AUTOSAR XML (schema 4-0-3)
standard types defined: UInt32
package /PATAC/MSM/ComponentTypes
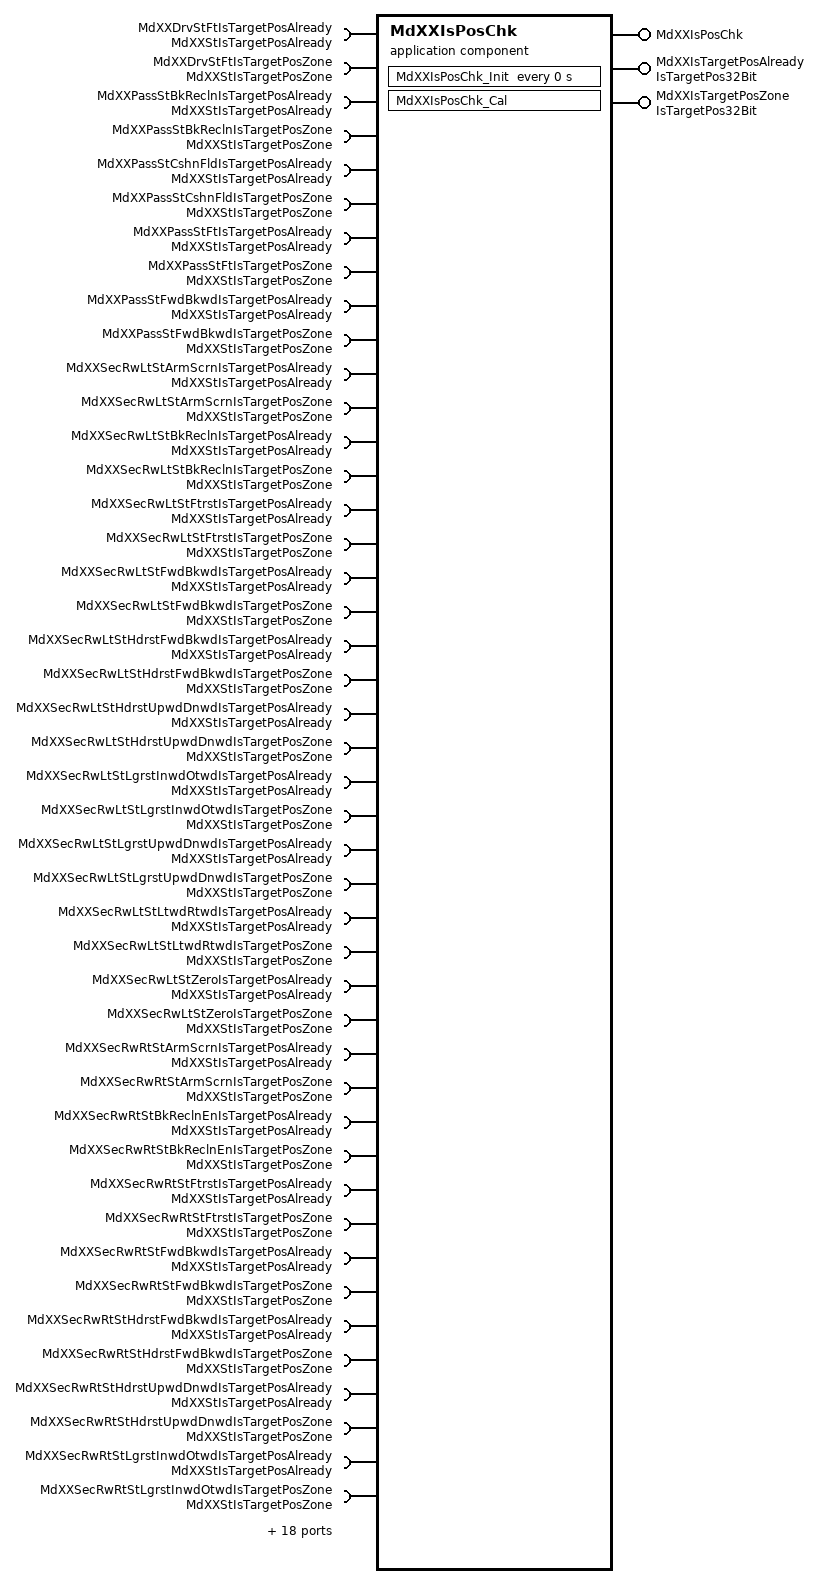
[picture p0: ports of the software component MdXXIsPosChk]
  application sw component type MdXXIsPosChk
    provide port MdXXIsPosChk: server-com-spec{operation=Cal, queue-length=1}, provided-interface=MdXXIsPosChk
    provide port MdXXIsTargetPosAlready: nonqueued-sender-com-spec{data-element=IsTargetPos32Bit/Val, init-value=0}, provided-interface=IsTargetPos32Bit
    provide port MdXXIsTargetPosZone: nonqueued-sender-com-spec{data-element=IsTargetPos32Bit/Val, init-value=0}, provided-interface=IsTargetPos32Bit
    62 x require port:
      MdXXDrvStFtIsTargetPosAlready: nonqueued-receiver-com-spec{data-element=MdXXStIsTargetPosAlready/Val, filter=data-filter-type=ALWAYS, init-value=0}, required-interface=MdXXStIsTargetPosAlready
      MdXXDrvStFtIsTargetPosZone: nonqueued-receiver-com-spec{data-element=MdXXStIsTargetPosZone/Val, filter=data-filter-type=ALWAYS, init-value=0}, required-interface=MdXXStIsTargetPosZone
      MdXXPassStBkReclnIsTargetPosAlready: nonqueued-receiver-com-spec{data-element=MdXXStIsTargetPosAlready/Val, filter=data-filter-type=ALWAYS, init-value=0}, required-interface=MdXXStIsTargetPosAlready
      MdXXPassStBkReclnIsTargetPosZone: nonqueued-receiver-com-spec{data-element=MdXXStIsTargetPosZone/Val, filter=data-filter-type=ALWAYS, init-value=0}, required-interface=MdXXStIsTargetPosZone
      MdXXPassStCshnFldIsTargetPosAlready: nonqueued-receiver-com-spec{data-element=MdXXStIsTargetPosAlready/Val, filter=data-filter-type=ALWAYS, init-value=0}, required-interface=MdXXStIsTargetPosAlready
      MdXXPassStCshnFldIsTargetPosZone: nonqueued-receiver-com-spec{data-element=MdXXStIsTargetPosZone/Val, filter=data-filter-type=ALWAYS, init-value=0}, required-interface=MdXXStIsTargetPosZone
      MdXXPassStFtIsTargetPosAlready: nonqueued-receiver-com-spec{data-element=MdXXStIsTargetPosAlready/Val, filter=data-filter-type=ALWAYS, init-value=0}, required-interface=MdXXStIsTargetPosAlready
      MdXXPassStFtIsTargetPosZone: nonqueued-receiver-com-spec{data-element=MdXXStIsTargetPosZone/Val, filter=data-filter-type=ALWAYS, init-value=0}, required-interface=MdXXStIsTargetPosZone
      MdXXPassStFwdBkwdIsTargetPosAlready: nonqueued-receiver-com-spec{data-element=MdXXStIsTargetPosAlready/Val, filter=data-filter-type=ALWAYS, init-value=0}, required-interface=MdXXStIsTargetPosAlready
      MdXXPassStFwdBkwdIsTargetPosZone: nonqueued-receiver-com-spec{data-element=MdXXStIsTargetPosZone/Val, filter=data-filter-type=ALWAYS, init-value=0}, required-interface=MdXXStIsTargetPosZone
      MdXXSecRwLtStArmScrnIsTargetPosAlready: nonqueued-receiver-com-spec{data-element=MdXXStIsTargetPosAlready/Val, filter=data-filter-type=ALWAYS, init-value=0}, required-interface=MdXXStIsTargetPosAlready
      MdXXSecRwLtStArmScrnIsTargetPosZone: nonqueued-receiver-com-spec{data-element=MdXXStIsTargetPosZone/Val, filter=data-filter-type=ALWAYS, init-value=0}, required-interface=MdXXStIsTargetPosZone
      MdXXSecRwLtStBkReclnIsTargetPosAlready: nonqueued-receiver-com-spec{data-element=MdXXStIsTargetPosAlready/Val, filter=data-filter-type=ALWAYS, init-value=0}, required-interface=MdXXStIsTargetPosAlready
      MdXXSecRwLtStBkReclnIsTargetPosZone: nonqueued-receiver-com-spec{data-element=MdXXStIsTargetPosZone/Val, filter=data-filter-type=ALWAYS, init-value=0}, required-interface=MdXXStIsTargetPosZone
      MdXXSecRwLtStFtrstIsTargetPosAlready: nonqueued-receiver-com-spec{data-element=MdXXStIsTargetPosAlready/Val, filter=data-filter-type=ALWAYS, init-value=0}, required-interface=MdXXStIsTargetPosAlready
      MdXXSecRwLtStFtrstIsTargetPosZone: nonqueued-receiver-com-spec{data-element=MdXXStIsTargetPosZone/Val, filter=data-filter-type=ALWAYS, init-value=0}, required-interface=MdXXStIsTargetPosZone
      MdXXSecRwLtStFwdBkwdIsTargetPosAlready: nonqueued-receiver-com-spec{data-element=MdXXStIsTargetPosAlready/Val, filter=data-filter-type=ALWAYS, init-value=0}, required-interface=MdXXStIsTargetPosAlready
      MdXXSecRwLtStFwdBkwdIsTargetPosZone: nonqueued-receiver-com-spec{data-element=MdXXStIsTargetPosZone/Val, filter=data-filter-type=ALWAYS, init-value=0}, required-interface=MdXXStIsTargetPosZone
      MdXXSecRwLtStHdrstFwdBkwdIsTargetPosAlready: nonqueued-receiver-com-spec{data-element=MdXXStIsTargetPosAlready/Val, filter=data-filter-type=ALWAYS, init-value=0}, required-interface=MdXXStIsTargetPosAlready
      MdXXSecRwLtStHdrstFwdBkwdIsTargetPosZone: nonqueued-receiver-com-spec{data-element=MdXXStIsTargetPosZone/Val, filter=data-filter-type=ALWAYS, init-value=0}, required-interface=MdXXStIsTargetPosZone
      MdXXSecRwLtStHdrstUpwdDnwdIsTargetPosAlready: nonqueued-receiver-com-spec{data-element=MdXXStIsTargetPosAlready/Val, filter=data-filter-type=ALWAYS, init-value=0}, required-interface=MdXXStIsTargetPosAlready
      MdXXSecRwLtStHdrstUpwdDnwdIsTargetPosZone: nonqueued-receiver-com-spec{data-element=MdXXStIsTargetPosZone/Val, filter=data-filter-type=ALWAYS, init-value=0}, required-interface=MdXXStIsTargetPosZone
      MdXXSecRwLtStLgrstInwdOtwdIsTargetPosAlready: nonqueued-receiver-com-spec{data-element=MdXXStIsTargetPosAlready/Val, filter=data-filter-type=ALWAYS, init-value=0}, required-interface=MdXXStIsTargetPosAlready
      MdXXSecRwLtStLgrstInwdOtwdIsTargetPosZone: nonqueued-receiver-com-spec{data-element=MdXXStIsTargetPosZone/Val, filter=data-filter-type=ALWAYS, init-value=0}, required-interface=MdXXStIsTargetPosZone
      MdXXSecRwLtStLgrstUpwdDnwdIsTargetPosAlready: nonqueued-receiver-com-spec{data-element=MdXXStIsTargetPosAlready/Val, filter=data-filter-type=ALWAYS, init-value=0}, required-interface=MdXXStIsTargetPosAlready
      MdXXSecRwLtStLgrstUpwdDnwdIsTargetPosZone: nonqueued-receiver-com-spec{data-element=MdXXStIsTargetPosZone/Val, filter=data-filter-type=ALWAYS, init-value=0}, required-interface=MdXXStIsTargetPosZone
      MdXXSecRwLtStLtwdRtwdIsTargetPosAlready: nonqueued-receiver-com-spec{data-element=MdXXStIsTargetPosAlready/Val, filter=data-filter-type=ALWAYS, init-value=0}, required-interface=MdXXStIsTargetPosAlready
      MdXXSecRwLtStLtwdRtwdIsTargetPosZone: nonqueued-receiver-com-spec{data-element=MdXXStIsTargetPosZone/Val, filter=data-filter-type=ALWAYS, init-value=0}, required-interface=MdXXStIsTargetPosZone
      MdXXSecRwLtStZeroIsTargetPosAlready: nonqueued-receiver-com-spec{data-element=MdXXStIsTargetPosAlready/Val, filter=data-filter-type=ALWAYS, init-value=0}, required-interface=MdXXStIsTargetPosAlready
      MdXXSecRwLtStZeroIsTargetPosZone: nonqueued-receiver-com-spec{data-element=MdXXStIsTargetPosZone/Val, filter=data-filter-type=ALWAYS, init-value=0}, required-interface=MdXXStIsTargetPosZone
      MdXXSecRwRtStArmScrnIsTargetPosAlready: nonqueued-receiver-com-spec{data-element=MdXXStIsTargetPosAlready/Val, filter=data-filter-type=ALWAYS, init-value=0}, required-interface=MdXXStIsTargetPosAlready
      MdXXSecRwRtStArmScrnIsTargetPosZone: nonqueued-receiver-com-spec{data-element=MdXXStIsTargetPosZone/Val, filter=data-filter-type=ALWAYS, init-value=0}, required-interface=MdXXStIsTargetPosZone
      MdXXSecRwRtStBkReclnEnIsTargetPosAlready: nonqueued-receiver-com-spec{data-element=MdXXStIsTargetPosAlready/Val, filter=data-filter-type=ALWAYS, init-value=0}, required-interface=MdXXStIsTargetPosAlready
      MdXXSecRwRtStBkReclnEnIsTargetPosZone: nonqueued-receiver-com-spec{data-element=MdXXStIsTargetPosZone/Val, filter=data-filter-type=ALWAYS, init-value=0}, required-interface=MdXXStIsTargetPosZone
      MdXXSecRwRtStFtrstIsTargetPosAlready: nonqueued-receiver-com-spec{data-element=MdXXStIsTargetPosAlready/Val, filter=data-filter-type=ALWAYS, init-value=0}, required-interface=MdXXStIsTargetPosAlready
      MdXXSecRwRtStFtrstIsTargetPosZone: nonqueued-receiver-com-spec{data-element=MdXXStIsTargetPosZone/Val, filter=data-filter-type=ALWAYS, init-value=0}, required-interface=MdXXStIsTargetPosZone
      MdXXSecRwRtStFwdBkwdIsTargetPosAlready: nonqueued-receiver-com-spec{data-element=MdXXStIsTargetPosAlready/Val, filter=data-filter-type=ALWAYS, init-value=0}, required-interface=MdXXStIsTargetPosAlready
      MdXXSecRwRtStFwdBkwdIsTargetPosZone: nonqueued-receiver-com-spec{data-element=MdXXStIsTargetPosZone/Val, filter=data-filter-type=ALWAYS, init-value=0}, required-interface=MdXXStIsTargetPosZone
      MdXXSecRwRtStHdrstFwdBkwdIsTargetPosAlready: nonqueued-receiver-com-spec{data-element=MdXXStIsTargetPosAlready/Val, filter=data-filter-type=ALWAYS, init-value=0}, required-interface=MdXXStIsTargetPosAlready
      MdXXSecRwRtStHdrstFwdBkwdIsTargetPosZone: nonqueued-receiver-com-spec{data-element=MdXXStIsTargetPosZone/Val, filter=data-filter-type=ALWAYS, init-value=0}, required-interface=MdXXStIsTargetPosZone
      MdXXSecRwRtStHdrstUpwdDnwdIsTargetPosAlready: nonqueued-receiver-com-spec{data-element=MdXXStIsTargetPosAlready/Val, filter=data-filter-type=ALWAYS, init-value=0}, required-interface=MdXXStIsTargetPosAlready
      MdXXSecRwRtStHdrstUpwdDnwdIsTargetPosZone: nonqueued-receiver-com-spec{data-element=MdXXStIsTargetPosZone/Val, filter=data-filter-type=ALWAYS, init-value=0}, required-interface=MdXXStIsTargetPosZone
      MdXXSecRwRtStLgrstInwdOtwdIsTargetPosAlready: nonqueued-receiver-com-spec{data-element=MdXXStIsTargetPosAlready/Val, filter=data-filter-type=ALWAYS, init-value=0}, required-interface=MdXXStIsTargetPosAlready
      MdXXSecRwRtStLgrstInwdOtwdIsTargetPosZone: nonqueued-receiver-com-spec{data-element=MdXXStIsTargetPosZone/Val, filter=data-filter-type=ALWAYS, init-value=0}, required-interface=MdXXStIsTargetPosZone
      MdXXSecRwRtStLgrstUpwdDnwdIsTargetPosAlready: nonqueued-receiver-com-spec{data-element=MdXXStIsTargetPosAlready/Val, filter=data-filter-type=ALWAYS, init-value=0}, required-interface=MdXXStIsTargetPosAlready
      MdXXSecRwRtStLgrstUpwdDnwdIsTargetPosZone: nonqueued-receiver-com-spec{data-element=MdXXStIsTargetPosZone/Val, filter=data-filter-type=ALWAYS, init-value=0}, required-interface=MdXXStIsTargetPosZone
      MdXXSecRwRtStLtwdRtwdIsTargetPosAlready: nonqueued-receiver-com-spec{data-element=MdXXStIsTargetPosAlready/Val, filter=data-filter-type=ALWAYS, init-value=0}, required-interface=MdXXStIsTargetPosAlready
      MdXXSecRwRtStLtwdRtwdIsTargetPosZone: nonqueued-receiver-com-spec{data-element=MdXXStIsTargetPosZone/Val, filter=data-filter-type=ALWAYS, init-value=0}, required-interface=MdXXStIsTargetPosZone
      MdXXSecRwRtStZeroIsTargetPosAlready: nonqueued-receiver-com-spec{data-element=MdXXStIsTargetPosAlready/Val, filter=data-filter-type=ALWAYS, init-value=0}, required-interface=MdXXStIsTargetPosAlready
      MdXXSecRwRtStZeroIsTargetPosZone: nonqueued-receiver-com-spec{data-element=MdXXStIsTargetPosZone/Val, filter=data-filter-type=ALWAYS, init-value=0}, required-interface=MdXXStIsTargetPosZone
      MdXXThdRwLtStBkReclnIsTargetPosAlready: nonqueued-receiver-com-spec{data-element=MdXXStIsTargetPosAlready/Val, filter=data-filter-type=ALWAYS, init-value=0}, required-interface=MdXXStIsTargetPosAlready
      MdXXThdRwLtStBkReclnIsTargetPosZone: nonqueued-receiver-com-spec{data-element=MdXXStIsTargetPosZone/Val, filter=data-filter-type=ALWAYS, init-value=0}, required-interface=MdXXStIsTargetPosZone
      MdXXThdRwLtStCshnFldIsTargetPosAlready: nonqueued-receiver-com-spec{data-element=MdXXStIsTargetPosAlready/Val, filter=data-filter-type=ALWAYS, init-value=0}, required-interface=MdXXStIsTargetPosAlready
      MdXXThdRwLtStCshnFldIsTargetPosZone: nonqueued-receiver-com-spec{data-element=MdXXStIsTargetPosZone/Val, filter=data-filter-type=ALWAYS, init-value=0}, required-interface=MdXXStIsTargetPosZone
      MdXXThdRwLtStFwdBkwdIsTargetPosAlready: nonqueued-receiver-com-spec{data-element=MdXXStIsTargetPosAlready/Val, filter=data-filter-type=ALWAYS, init-value=0}, required-interface=MdXXStIsTargetPosAlready
      MdXXThdRwLtStFwdBkwdIsTargetPosZone: nonqueued-receiver-com-spec{data-element=MdXXStIsTargetPosZone/Val, filter=data-filter-type=ALWAYS, init-value=0}, required-interface=MdXXStIsTargetPosZone
      MdXXThdRwRtStBkReclnIsTargetPosAlready: nonqueued-receiver-com-spec{data-element=MdXXStIsTargetPosAlready/Val, filter=data-filter-type=ALWAYS, init-value=0}, required-interface=MdXXStIsTargetPosAlready
      MdXXThdRwRtStBkReclnIsTargetPosZone: nonqueued-receiver-com-spec{data-element=MdXXStIsTargetPosZone/Val, filter=data-filter-type=ALWAYS, init-value=0}, required-interface=MdXXStIsTargetPosZone
      MdXXThdRwRtStCshnFldIsTargetPosAlready: nonqueued-receiver-com-spec{data-element=MdXXStIsTargetPosAlready/Val, filter=data-filter-type=ALWAYS, init-value=0}, required-interface=MdXXStIsTargetPosAlready
      MdXXThdRwRtStCshnFldIsTargetPosZone: nonqueued-receiver-com-spec{data-element=MdXXStIsTargetPosZone/Val, filter=data-filter-type=ALWAYS, init-value=0}, required-interface=MdXXStIsTargetPosZone
      MdXXThdRwRtStFwdBkwdIsTargetPosAlready: nonqueued-receiver-com-spec{data-element=MdXXStIsTargetPosAlready/Val, filter=data-filter-type=ALWAYS, init-value=0}, required-interface=MdXXStIsTargetPosAlready
      MdXXThdRwRtStFwdBkwdIsTargetPosZone: nonqueued-receiver-com-spec{data-element=MdXXStIsTargetPosZone/Val, filter=data-filter-type=ALWAYS, init-value=0}, required-interface=MdXXStIsTargetPosZone
    behavior MdXXIsPosChk_InternalBehavior
      operation invoked event OIT_MdXXIsPosChk_Cal_MdXXIsPosChk_Cal: start-on-event=MdXXIsPosChk_Cal, operation=MdXXIsPosChk.Cal
      timing event MdXXIsPosChk_InitEvent: start-on-event=MdXXIsPosChk_Init, period=0
      runnable MdXXIsPosChk_Cal
        data-receive-point-by-arguments:
          62 x access:
            REC_MdXXDrvStFtIsTargetPosAlready_Val: accessed-variable=MdXXDrvStFtIsTargetPosAlready.Val
            REC_MdXXDrvStFtIsTargetPosZone_Val: accessed-variable=MdXXDrvStFtIsTargetPosZone.Val
            REC_MdXXPassStBkReclnIsTargetPosAlready_Val: accessed-variable=MdXXPassStBkReclnIsTargetPosAlready.Val
            REC_MdXXPassStBkReclnIsTargetPosZone_Val: accessed-variable=MdXXPassStBkReclnIsTargetPosZone.Val
            REC_MdXXPassStCshnFldIsTargetPosAlready_Val: accessed-variable=MdXXPassStCshnFldIsTargetPosAlready.Val
            REC_MdXXPassStCshnFldIsTargetPosZone_Val: accessed-variable=MdXXPassStCshnFldIsTargetPosZone.Val
            REC_MdXXPassStFtIsTargetPosAlready_Val: accessed-variable=MdXXPassStFtIsTargetPosAlready.Val
            REC_MdXXPassStFtIsTargetPosZone_Val: accessed-variable=MdXXPassStFtIsTargetPosZone.Val
            REC_MdXXPassStFwdBkwdIsTargetPosAlready_Val: accessed-variable=MdXXPassStFwdBkwdIsTargetPosAlready.Val
            REC_MdXXPassStFwdBkwdIsTargetPosZone_Val: accessed-variable=MdXXPassStFwdBkwdIsTargetPosZone.Val
            REC_MdXXSecRwLtStArmScrnIsTargetPosAlready_Val: accessed-variable=MdXXSecRwLtStArmScrnIsTargetPosAlready.Val
            REC_MdXXSecRwLtStArmScrnIsTargetPosZone_Val: accessed-variable=MdXXSecRwLtStArmScrnIsTargetPosZone.Val
            REC_MdXXSecRwLtStBkReclnIsTargetPosAlready_Val: accessed-variable=MdXXSecRwLtStBkReclnIsTargetPosAlready.Val
            REC_MdXXSecRwLtStBkReclnIsTargetPosZone_Val: accessed-variable=MdXXSecRwLtStBkReclnIsTargetPosZone.Val
            REC_MdXXSecRwLtStFtrstIsTargetPosAlready_Val: accessed-variable=MdXXSecRwLtStFtrstIsTargetPosAlready.Val
            REC_MdXXSecRwLtStFtrstIsTargetPosZone_Val: accessed-variable=MdXXSecRwLtStFtrstIsTargetPosZone.Val
            REC_MdXXSecRwLtStFwdBkwdIsTargetPosAlready_Val: accessed-variable=MdXXSecRwLtStFwdBkwdIsTargetPosAlready.Val
            REC_MdXXSecRwLtStFwdBkwdIsTargetPosZone_Val: accessed-variable=MdXXSecRwLtStFwdBkwdIsTargetPosZone.Val
            REC_MdXXSecRwLtStHdrstFwdBkwdIsTargetPosAlready_Val: accessed-variable=MdXXSecRwLtStHdrstFwdBkwdIsTargetPosAlready.Val
            REC_MdXXSecRwLtStHdrstFwdBkwdIsTargetPosZone_Val: accessed-variable=MdXXSecRwLtStHdrstFwdBkwdIsTargetPosZone.Val
            REC_MdXXSecRwLtStHdrstUpwdDnwdIsTargetPosAlready_Val: accessed-variable=MdXXSecRwLtStHdrstUpwdDnwdIsTargetPosAlready.Val
            REC_MdXXSecRwLtStHdrstUpwdDnwdIsTargetPosZone_Val: accessed-variable=MdXXSecRwLtStHdrstUpwdDnwdIsTargetPosZone.Val
            REC_MdXXSecRwLtStLgrstInwdOtwdIsTargetPosAlready_Val: accessed-variable=MdXXSecRwLtStLgrstInwdOtwdIsTargetPosAlready.Val
            REC_MdXXSecRwLtStLgrstInwdOtwdIsTargetPosZone_Val: accessed-variable=MdXXSecRwLtStLgrstInwdOtwdIsTargetPosZone.Val
            REC_MdXXSecRwLtStLgrstUpwdDnwdIsTargetPosAlready_Val: accessed-variable=MdXXSecRwLtStLgrstUpwdDnwdIsTargetPosAlready.Val
            REC_MdXXSecRwLtStLgrstUpwdDnwdIsTargetPosZone_Val: accessed-variable=MdXXSecRwLtStLgrstUpwdDnwdIsTargetPosZone.Val
            REC_MdXXSecRwLtStLtwdRtwdIsTargetPosAlready_Val: accessed-variable=MdXXSecRwLtStLtwdRtwdIsTargetPosAlready.Val
            REC_MdXXSecRwLtStLtwdRtwdIsTargetPosZone_Val: accessed-variable=MdXXSecRwLtStLtwdRtwdIsTargetPosZone.Val
            REC_MdXXSecRwLtStZeroIsTargetPosAlready_Val: accessed-variable=MdXXSecRwLtStZeroIsTargetPosAlready.Val
            REC_MdXXSecRwLtStZeroIsTargetPosZone_Val: accessed-variable=MdXXSecRwLtStZeroIsTargetPosZone.Val
            REC_MdXXSecRwRtStArmScrnIsTargetPosAlready_Val: accessed-variable=MdXXSecRwRtStArmScrnIsTargetPosAlready.Val
            REC_MdXXSecRwRtStArmScrnIsTargetPosZone_Val: accessed-variable=MdXXSecRwRtStArmScrnIsTargetPosZone.Val
            REC_MdXXSecRwRtStBkReclnEnIsTargetPosAlready_Val: accessed-variable=MdXXSecRwRtStBkReclnEnIsTargetPosAlready.Val
            REC_MdXXSecRwRtStBkReclnEnIsTargetPosZone_Val: accessed-variable=MdXXSecRwRtStBkReclnEnIsTargetPosZone.Val
            REC_MdXXSecRwRtStFtrstIsTargetPosAlready_Val: accessed-variable=MdXXSecRwRtStFtrstIsTargetPosAlready.Val
            REC_MdXXSecRwRtStFtrstIsTargetPosZone_Val: accessed-variable=MdXXSecRwRtStFtrstIsTargetPosZone.Val
            REC_MdXXSecRwRtStFwdBkwdIsTargetPosAlready_Val: accessed-variable=MdXXSecRwRtStFwdBkwdIsTargetPosAlready.Val
            REC_MdXXSecRwRtStFwdBkwdIsTargetPosZone_Val: accessed-variable=MdXXSecRwRtStFwdBkwdIsTargetPosZone.Val
            REC_MdXXSecRwRtStHdrstFwdBkwdIsTargetPosAlready_Val: accessed-variable=MdXXSecRwRtStHdrstFwdBkwdIsTargetPosAlready.Val
            REC_MdXXSecRwRtStHdrstFwdBkwdIsTargetPosZone_Val: accessed-variable=MdXXSecRwRtStHdrstFwdBkwdIsTargetPosZone.Val
            REC_MdXXSecRwRtStHdrstUpwdDnwdIsTargetPosAlready_Val: accessed-variable=MdXXSecRwRtStHdrstUpwdDnwdIsTargetPosAlready.Val
            REC_MdXXSecRwRtStHdrstUpwdDnwdIsTargetPosZone_Val: accessed-variable=MdXXSecRwRtStHdrstUpwdDnwdIsTargetPosZone.Val
            REC_MdXXSecRwRtStLgrstInwdOtwdIsTargetPosAlready_Val: accessed-variable=MdXXSecRwRtStLgrstInwdOtwdIsTargetPosAlready.Val
            REC_MdXXSecRwRtStLgrstInwdOtwdIsTargetPosZone_Val: accessed-variable=MdXXSecRwRtStLgrstInwdOtwdIsTargetPosZone.Val
            REC_MdXXSecRwRtStLgrstUpwdDnwdIsTargetPosAlready_Val: accessed-variable=MdXXSecRwRtStLgrstUpwdDnwdIsTargetPosAlready.Val
            REC_MdXXSecRwRtStLgrstUpwdDnwdIsTargetPosZone_Val: accessed-variable=MdXXSecRwRtStLgrstUpwdDnwdIsTargetPosZone.Val
            REC_MdXXSecRwRtStLtwdRtwdIsTargetPosAlready_Val: accessed-variable=MdXXSecRwRtStLtwdRtwdIsTargetPosAlready.Val
            REC_MdXXSecRwRtStLtwdRtwdIsTargetPosZone_Val: accessed-variable=MdXXSecRwRtStLtwdRtwdIsTargetPosZone.Val
            REC_MdXXSecRwRtStZeroIsTargetPosAlready_Val: accessed-variable=MdXXSecRwRtStZeroIsTargetPosAlready.Val
            REC_MdXXSecRwRtStZeroIsTargetPosZone_Val: accessed-variable=MdXXSecRwRtStZeroIsTargetPosZone.Val
            REC_MdXXThdRwLtStBkReclnIsTargetPosAlready_Val: accessed-variable=MdXXThdRwLtStBkReclnIsTargetPosAlready.Val
            REC_MdXXThdRwLtStBkReclnIsTargetPosZone_Val: accessed-variable=MdXXThdRwLtStBkReclnIsTargetPosZone.Val
            REC_MdXXThdRwLtStCshnFldIsTargetPosAlready_Val: accessed-variable=MdXXThdRwLtStCshnFldIsTargetPosAlready.Val
            REC_MdXXThdRwLtStCshnFldIsTargetPosZone_Val: accessed-variable=MdXXThdRwLtStCshnFldIsTargetPosZone.Val
            REC_MdXXThdRwLtStFwdBkwdIsTargetPosAlready_Val: accessed-variable=MdXXThdRwLtStFwdBkwdIsTargetPosAlready.Val
            REC_MdXXThdRwLtStFwdBkwdIsTargetPosZone_Val: accessed-variable=MdXXThdRwLtStFwdBkwdIsTargetPosZone.Val
            REC_MdXXThdRwRtStBkReclnIsTargetPosAlready_Val: accessed-variable=MdXXThdRwRtStBkReclnIsTargetPosAlready.Val
            REC_MdXXThdRwRtStBkReclnIsTargetPosZone_Val: accessed-variable=MdXXThdRwRtStBkReclnIsTargetPosZone.Val
            REC_MdXXThdRwRtStCshnFldIsTargetPosAlready_Val: accessed-variable=MdXXThdRwRtStCshnFldIsTargetPosAlready.Val
            REC_MdXXThdRwRtStCshnFldIsTargetPosZone_Val: accessed-variable=MdXXThdRwRtStCshnFldIsTargetPosZone.Val
            REC_MdXXThdRwRtStFwdBkwdIsTargetPosAlready_Val: accessed-variable=MdXXThdRwRtStFwdBkwdIsTargetPosAlready.Val
            REC_MdXXThdRwRtStFwdBkwdIsTargetPosZone_Val: accessed-variable=MdXXThdRwRtStFwdBkwdIsTargetPosZone.Val
        data-send-points:
          access SEND_MdXXIsTargetPosAlready_Val: accessed-variable=MdXXIsTargetPosAlready.Val
          access SEND_MdXXIsTargetPosZone_Val: accessed-variable=MdXXIsTargetPosZone.Val
      runnable MdXXIsPosChk_Init
  swc implementation MdXXIsPosChk_Implementation: behavior=MdXXIsPosChk_InternalBehavior
    code-descriptors:
      code Default: artifact-descriptors=autosar-engineering-object={short-label=Default, category=SWSRC}
package /PATAC/MSM/ModeAdjust/PortInterface
  client server interface MdXXIsPosChk
    operation Cal
  sender receiver interface IsTargetPos32Bit: invalidation-policy{data-element=IsTargetPos32Bit/Val, handle-invalid=DONT-INVALIDATE}
    data Val: type=UInt32
  sender receiver interface MdXXStIsTargetPosAlready: invalidation-policy{data-element=MdXXStIsTargetPosAlready/Val, handle-invalid=DONT-INVALIDATE}
    data Val: type=UInt32
  sender receiver interface MdXXStIsTargetPosZone: invalidation-policy{data-element=MdXXStIsTargetPosZone/Val, handle-invalid=DONT-INVALIDATE}
    data Val: type=UInt32
